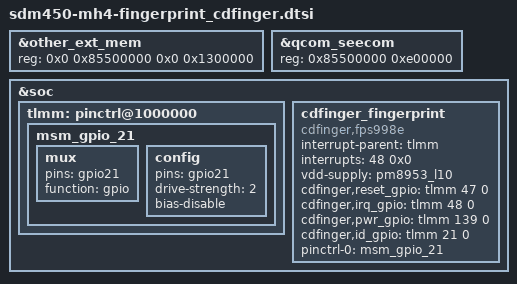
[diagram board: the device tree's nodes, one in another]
/*
 * Copyright (c) 2015-2017, The Linux Foundation. All rights reserved.
 *
 * This program is free software; you can redistribute it and/or modify
 * it under the terms of the GNU General Public License version 2 and
 * only version 2 as published by the Free Software Foundation.
 *
 * This program is distributed in the hope that it will be useful,
 * but WITHOUT ANY WARRANTY; without even the implied warranty of
 * MERCHANTABILITY or FITNESS FOR A PARTICULAR PURPOSE.  See the
 * GNU General Public License for more details.
 */

&other_ext_mem {
	reg = <0x0 0x85500000 0x0 0x1300000>;
};

&qcom_seecom {
	reg = <0x85500000 0xe00000>;
};

&soc {

	tlmm: pinctrl@1000000 {
		msm_gpio_21: msm_gpio_21 {
			mux {
				pins = "gpio21";
				function = "gpio";
			};
			config {
				pins = "gpio21";
				drive-strength = <2>;
				bias-disable;
			};
		};
	};

	cdfinger_fingerprint {
		compatible = "cdfinger,fps998e";
		interrupt-parent = <&tlmm>;
		interrupts = <48 0x0>;
		vdd-supply  = <&pm8953_l10>;
		cdfinger,reset_gpio = <&tlmm 47 0>;
		cdfinger,irq_gpio = <&tlmm 48 0>;
		cdfinger,pwr_gpio = <&tlmm 139 0>;
		cdfinger,id_gpio = <&tlmm 21 0>;
		pinctrl-names = "cdfinger_id_pin";
		pinctrl-0 = <&msm_gpio_21>;
	};
};
